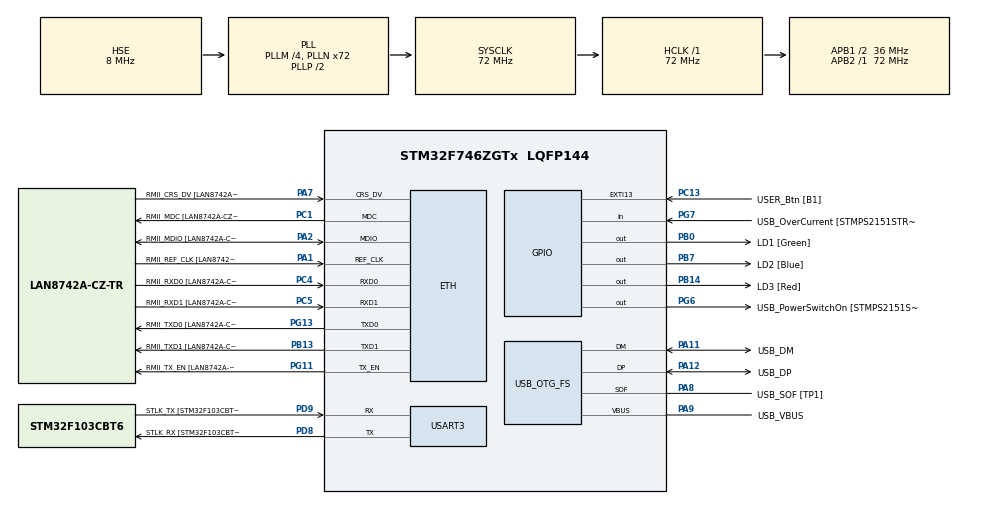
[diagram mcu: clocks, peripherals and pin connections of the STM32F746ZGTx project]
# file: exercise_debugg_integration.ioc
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ETH.MediaInterface=HAL_ETH_RMII_MODE
ETH.PHY_Name=LAN8742A_PHY_ADDRESS
ETH.PHY_Value=0
ETH.PhyAddress=0
FREERTOS.Tasks01=defaultTask,24,128,StartDefaultTask,Default,NULL,Dynamic,NULL,NULL
FREERTOS.configUSE_NEWLIB_REENTRANT=1
Mcu.Family=STM32F7
Mcu.Name=STM32F746ZGTx
Mcu.Package=LQFP144
NVIC.PriorityGroup=NVIC_PRIORITYGROUP_4
NVIC.TIM1_UP_TIM10_IRQn=true\:15\:0\:false\:false\:true\:false\:false\:true\:true
NVIC.TimeBase=TIM1_UP_TIM10_IRQn
NVIC.TimeBaseIP=TIM1
PA1.GPIO_Label=RMII_REF_CLK [LAN8742A-CZ-TR_REFCLK0]
PA1.Mode=RMII
PA1.Signal=ETH_REF_CLK
PA10.GPIO_Label=USB_ID
PA10.Signal=USB_OTG_FS_ID
PA11.GPIO_Label=USB_DM
PA11.Mode=Device_Only
PA11.Signal=USB_OTG_FS_DM
PA12.GPIO_Label=USB_DP
PA12.Mode=Device_Only
PA12.Signal=USB_OTG_FS_DP
PA13.GPIO_Label=TMS
PA13.Mode=Serial_Wire
PA13.Signal=SYS_JTMS-SWDIO
PA14.GPIO_Label=TCK
PA14.Mode=Serial_Wire
PA14.Signal=SYS_JTCK-SWCLK
PA2.GPIO_Label=RMII_MDIO [LAN8742A-CZ-TR_MDIO]
PA2.Mode=RMII
PA2.Signal=ETH_MDIO
PA7.GPIO_Label=RMII_CRS_DV [LAN8742A-CZ-TR_CRS_DV]
PA7.Mode=RMII
PA7.Signal=ETH_CRS_DV
PA8.GPIO_Label=USB_SOF [TP1]
PA8.Mode=Activate_SOF_FS
PA8.Signal=USB_OTG_FS_SOF
PA9.GPIO_Label=USB_VBUS
PA9.Mode=Activate_VBUS
PA9.Signal=USB_OTG_FS_VBUS
PB0.GPIO_Label=LD1 [Green]
PB0.Signal=GPIO_Output
PB13.GPIO_Label=RMII_TXD1 [LAN8742A-CZ-TR_TXD1]
PB13.Mode=RMII
PB13.Signal=ETH_TXD1
PB14.GPIO_Label=LD3 [Red]
PB14.Signal=GPIO_Output
PB3.GPIO_Label=SW0
PB3.Signal=SYS_JTDO-SWO
PB7.GPIO_Label=LD2 [Blue]
PB7.Signal=GPIO_Output
PC1.GPIO_Label=RMII_MDC [LAN8742A-CZ-TR_MDC]
PC1.Mode=RMII
PC1.Signal=ETH_MDC
PC13.GPIO_Label=USER_Btn [B1]
PC13.Signal=GPXTI13
PC14/OSC32_IN.Mode=LSE-External-Oscillator
PC14/OSC32_IN.Signal=RCC_OSC32_IN
PC15/OSC32_OUT.Mode=LSE-External-Oscillator
PC15/OSC32_OUT.Signal=RCC_OSC32_OUT
PC4.GPIO_Label=RMII_RXD0 [LAN8742A-CZ-TR_RXD0]
PC4.Mode=RMII
PC4.Signal=ETH_RXD0
PC5.GPIO_Label=RMII_RXD1 [LAN8742A-CZ-TR_RXD1]
PC5.Mode=RMII
PC5.Signal=ETH_RXD1
PD8.GPIO_Label=STLK_RX [STM32F103CBT6_PA3]
PD8.GPIO_PuPd=GPIO_PULLUP
PD8.Mode=Asynchronous
PD8.Signal=USART3_TX
PD9.GPIO_Label=STLK_TX [STM32F103CBT6_PA2]
PD9.GPIO_PuPd=GPIO_PULLUP
PD9.Mode=Asynchronous
PD9.Signal=USART3_RX
PG11.GPIO_Label=RMII_TX_EN [LAN8742A-CZ-TR_TXEN]
PG11.Mode=RMII
PG11.Signal=ETH_TX_EN
PG13.GPIO_Label=RMII_TXD0 [LAN8742A-CZ-TR_TXD0]
PG13.Mode=RMII
PG13.Signal=ETH_TXD0
PG6.GPIO_Label=USB_PowerSwitchOn [STMPS2151STR_EN]
PG6.Signal=GPIO_Output
PG7.GPIO_Label=USB_OverCurrent [STMPS2151STR_FAULT]
PG7.Signal=GPIO_Input
PH0/OSC_IN.GPIO_Label=MCO [STM32F103CBT6_PA8]
PH0/OSC_IN.Mode=HSE-External-Clock-Source
PH0/OSC_IN.Signal=RCC_OSC_IN
PH1/OSC_OUT.Mode=HSE-External-Clock-Source
PH1/OSC_OUT.Signal=RCC_OSC_OUT
ProjectManager.HeapSize=0x200
ProjectManager.StackSize=0x400
ProjectManager.TargetToolchain=STM32CubeIDE
RCC.48MHZClocksFreq_Value=24000000
RCC.AHBFreq_Value=72000000
RCC.APB1CLKDivider=RCC_HCLK_DIV2
RCC.APB1Freq_Value=36000000
RCC.APB1TimFreq_Value=72000000
RCC.APB2Freq_Value=72000000
RCC.APB2TimFreq_Value=72000000
RCC.CortexFreq_Value=72000000
RCC.HCLKFreq_Value=72000000
RCC.HSE_VALUE=8000000
RCC.HSI_VALUE=16000000
RCC.PLLM=4
RCC.PLLMUL=RCC_PLL_MUL9
RCC.PLLN=72
RCC.PLLQ=3
RCC.PRESCALERUSB=RCC_USBCLKSOURCE_PLL_DIV1_5
RCC.SYSCLKFreq_VALUE=72000000
RCC.SYSCLKSource=RCC_SYSCLKSOURCE_PLLCLK
RCC.SYSCLKSourceVirtual=RCC_SYSCLKSOURCE_PLLCLK
RCC.USBFreq_Value=48000000
RCC.VCOOutputFreq_Value=144000000
USART3.VirtualMode-Asynchronous=VM_ASYNC
USB_OTG_FS.VirtualMode=Device_Only
VP_FREERTOS_VS_CMSIS_V2.Mode=CMSIS_V2
VP_SYS_VS_tim1.Mode=TIM1
board=NUCLEO-F746ZG

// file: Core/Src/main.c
/* USER CODE BEGIN Header */
/**
  ******************************************************************************
  * @file           : main.c
  * @brief          : Main program body
  ******************************************************************************
  * @attention
  *
  * Copyright (c) 2024 STMicroelectronics.
  * All rights reserved.
  *
  * This software is licensed under terms that can be found in the LICENSE file
  * in the root directory of this software component.
  * If no LICENSE file comes with this software, it is provided AS-IS.
  *
  ******************************************************************************
  */
/* USER CODE END Header */
#include "main.h"
#include "string.h"
#include "freeRTOS.h"
#include "task.h"
#include <semphr.h>
#include <SEGGER_SYSVIEW.h>
#include <stm32f7xx_hal.h>
#include <lookBusy.h>

/* USER CODE BEGIN PTD */
#define STACK_SIZE 128

static void blinkTwice( LED* led );

void TaskA( void * argument);
void TaskB( void* argumet );
void TaskC( void* argumet );
/* USER CODE END PTD */

/* USER CODE BEGIN PD */

// Create storage for a pointer to a semaphore

SemaphoreHandle_t mutexPtr = NULL;

/* USER CODE END PD */

// Define the stack and the the task control block (TCB) for RedTask to use

#if defined ( __ICCARM__ ) /*!< IAR Compiler */
#pragma location=0x2004c000
ETH_DMADescTypeDef  DMARxDscrTab[ETH_RX_DESC_CNT]; /* Ethernet Rx DMA Descriptors */
#pragma location=0x2004c0a0
ETH_DMADescTypeDef  DMATxDscrTab[ETH_TX_DESC_CNT]; /* Ethernet Tx DMA Descriptors */

#elif defined ( __CC_ARM )  /* MDK ARM Compiler */

__attribute__((at(0x2004c000))) ETH_DMADescTypeDef  DMARxDscrTab[ETH_RX_DESC_CNT]; /* Ethernet Rx DMA Descriptors */
__attribute__((at(0x2004c0a0))) ETH_DMADescTypeDef  DMATxDscrTab[ETH_TX_DESC_CNT]; /* Ethernet Tx DMA Descriptors */

#elif defined ( __GNUC__ ) /* GNU Compiler */

ETH_DMADescTypeDef DMARxDscrTab[ETH_RX_DESC_CNT] __attribute__((section(".RxDecripSection"))); /* Ethernet Rx DMA Descriptors */
ETH_DMADescTypeDef DMATxDscrTab[ETH_TX_DESC_CNT] __attribute__((section(".TxDecripSection")));   /* Ethernet Tx DMA Descriptors */
#endif

ETH_TxPacketConfig TxConfig;

ETH_HandleTypeDef heth;

UART_HandleTypeDef huart3;

PCD_HandleTypeDef hpcd_USB_OTG_FS;

/* Definitions for defaultTask */

void SystemClock_Config(void);
static void MX_GPIO_Init(void);
static void MX_ETH_Init(void);
static void MX_USART3_UART_Init(void);
static void MX_USB_OTG_FS_PCD_Init(void);
void StartDefaultTask(void *argument);

uint32_t iterationsPerMilliSecond;

int main(void)
{

	BaseType_t status;
	  HAL_Init();
	  SystemClock_Config();
	  MX_GPIO_Init();
	  MX_ETH_Init();
	  MX_USART3_UART_Init();
	  MX_USB_OTG_FS_PCD_Init();

		SEGGER_SYSVIEW_Conf();
		HAL_NVIC_SetPriorityGrouping(NVIC_PRIORITYGROUP_4);	//ensure proper priority grouping for freeRTOS

		// Get the iteration-rate for lookBusy()
		    iterationsPerMilliSecond = lookBusyIterationRate();

		    // Create a mutex .
		    // Note this is just a special case of a binary semaphore.
		    mutexPtr = xSemaphoreCreateMutex();
		    assert_param(mutexPtr != NULL);

		    assert_param(xTaskCreate(TaskA, "TaskA", STACK_SIZE, NULL, tskIDLE_PRIORITY + 3, NULL) == pdPASS);
		    assert_param(xTaskCreate(TaskB, "TaskB", STACK_SIZE, NULL, tskIDLE_PRIORITY + 2, NULL) == pdPASS);
		    assert_param(xTaskCreate(TaskC, "TaskC", STACK_SIZE, NULL, tskIDLE_PRIORITY + 1, NULL) == pdPASS);

		    // Start the scheduler - shouldn't return unless there's a problem
		    vTaskStartScheduler();

		    // If you've wound up here, there is likely an issue with over-running the freeRTOS heap
		    while(1)
		    {
		    }

}

/**
 * GreenTaskA periodically 'gives' semaphorePtr
 * NOTES:
 * - This semaphore isn't "given" to any task specifically
 * - Giving the semaphore doesn't prevent GreenTaskA from continuing to run.
 * - Note the green LED continues to blink at all times
 */
/**
 * Task A is the highest priority task in the system.
 * It periodically takes the mutex with a 200ms timeout.
 * If the mutex is taken within 200 ms, the red LED is turned off,
   and blinkTwice() is called to blink the green LED.
 * If the mutex is not taken within 200ms, the red LED is turned on
   (after TaskA has been given context)
 * At the end of each while-loop iteration, vTaskDelay is called.
 */
void TaskA( void* argument )
{
    uint32_t receivedCounter = 0;
    uint32_t timedoutCounter = 0;
    while(1)
    {
        // 'take' the mutex with a 200mS timeout
        SEGGER_SYSVIEW_PrintfHost("attempt to take mutex");
        if(xSemaphoreTake(mutexPtr, 200/portTICK_PERIOD_MS) == pdPASS)
        {
        	HAL_GPIO_WritePin(GPIOB, GPIO_PIN_14, GPIO_PIN_RESET);
            receivedCounter++;
            // In calling SEGGER_SYSVIEW_PrintfHost, the space between the %u and the closing
            // quote appears to be a necessary work-around for a bug in the API.
            SEGGER_SYSVIEW_PrintfHost("received mutexPtr: %u ", receivedCounter);
            blinkTwice(&GreenLed);
            xSemaphoreGive(mutexPtr);
        }
        else
        {
            // This code is called when the mutex wasn't taken in time
            timedoutCounter++;
            SEGGER_SYSVIEW_PrintfHost("FAILED to take mutex in time: %u ", timedoutCounter);
            HAL_GPIO_WritePin(GPIOB, GPIO_PIN_14, GPIO_PIN_SET);
        }
        // Sleep for a bit to let other tasks run
        // StmRand will return a random number between 5 and 30 (inclusive).
        vTaskDelay(StmRand(5,30));
    }
}

/**
 * This medium priority task just wakes up periodically and wastes time.
 */
void TaskB( void* argument )
{
    uint32_t counter = 0;
    uint32_t spinTime;
    uint32_t i;

    while(1)
    {
        counter++;
        SEGGER_SYSVIEW_PrintfHost("starting iteration %u ", counter);
        vTaskDelay(StmRand(10,25));

        // Each for-loop iteration takes 1 ms of processing time.
        // The for-loop, as a whole, will use 30-75 ms of processing time.
        spinTime = StmRand(30,75);
        for (i=0; i<spinTime; i++){
            lookBusy(iterationsPerMilliSecond);
        }
    }
}

/**
 * The lowest priority task in the system.
 * It is the same as TaskA, except:
   * It calls blinkTwice() to blink the blue LED.
   * It does not call vTaskDelay().
 */
void TaskC( void* argument )
{
    uint32_t receivedCounter = 0;
    uint32_t timedoutCounter = 0;

    while(1)
    {
        // 'take' the mutex with a 200mS timeout
        SEGGER_SYSVIEW_PrintfHost("attempt to take mutex");
        if(xSemaphoreTake(mutexPtr, 200/portTICK_PERIOD_MS) == pdPASS)
        {
        	HAL_GPIO_WritePin(GPIOB, GPIO_PIN_14, GPIO_PIN_RESET);
            receivedCounter++;
            SEGGER_SYSVIEW_PrintfHost("mutex taken: %u ", receivedCounter);
            blinkTwice(&BlueLed);
            xSemaphoreGive(mutexPtr);
        }
        else
        {
            // This code is called when the mutex wasn't taken in time
            timedoutCounter++;
            SEGGER_SYSVIEW_PrintfHost("FAILED to take mutex in time: %u ", timedoutCounter);
            HAL_GPIO_WritePin(GPIOB, GPIO_PIN_14, GPIO_PIN_SET);
        }
    }
}

/**
 * Blink the desired LED twice
 */
static void blinkTwice( LED* led )
{
    for(uint32_t i = 0; i < 2; i++)
    {
        led->On();
        vTaskDelay(25/portTICK_PERIOD_MS);
        led->Off();
        vTaskDelay(25/portTICK_PERIOD_MS);
    }
}

void SystemClock_Config(void)
{
  RCC_OscInitTypeDef RCC_OscInitStruct = {0};
  RCC_ClkInitTypeDef RCC_ClkInitStruct = {0};

  /** Configure LSE Drive Capability
  */
  HAL_PWR_EnableBkUpAccess();

  /** Configure the main internal regulator output voltage
  */
  __HAL_RCC_PWR_CLK_ENABLE();
  __HAL_PWR_VOLTAGESCALING_CONFIG(PWR_REGULATOR_VOLTAGE_SCALE3);

  /** Initializes the RCC Oscillators according to the specified parameters
  * in the RCC_OscInitTypeDef structure.
  */
  RCC_OscInitStruct.OscillatorType = RCC_OSCILLATORTYPE_HSE;
  RCC_OscInitStruct.HSEState = RCC_HSE_BYPASS;
  RCC_OscInitStruct.PLL.PLLState = RCC_PLL_ON;
  RCC_OscInitStruct.PLL.PLLSource = RCC_PLLSOURCE_HSE;
  RCC_OscInitStruct.PLL.PLLM = 4;
  RCC_OscInitStruct.PLL.PLLN = 72;
  RCC_OscInitStruct.PLL.PLLP = RCC_PLLP_DIV2;
  RCC_OscInitStruct.PLL.PLLQ = 3;
  if (HAL_RCC_OscConfig(&RCC_OscInitStruct) != HAL_OK)
  {
    Error_Handler();
  }

  /** Initializes the CPU, AHB and APB buses clocks
  */
  RCC_ClkInitStruct.ClockType = RCC_CLOCKTYPE_HCLK|RCC_CLOCKTYPE_SYSCLK
                              |RCC_CLOCKTYPE_PCLK1|RCC_CLOCKTYPE_PCLK2;
  RCC_ClkInitStruct.SYSCLKSource = RCC_SYSCLKSOURCE_PLLCLK;
  RCC_ClkInitStruct.AHBCLKDivider = RCC_SYSCLK_DIV1;
  RCC_ClkInitStruct.APB1CLKDivider = RCC_HCLK_DIV2;
  RCC_ClkInitStruct.APB2CLKDivider = RCC_HCLK_DIV1;

  if (HAL_RCC_ClockConfig(&RCC_ClkInitStruct, FLASH_LATENCY_2) != HAL_OK)
  {
    Error_Handler();
  }
}

static void MX_ETH_Init(void)
{

   static uint8_t MACAddr[6];

  heth.Instance = ETH;
  MACAddr[0] = 0x00;
  MACAddr[1] = 0x80;
  MACAddr[2] = 0xE1;
  MACAddr[3] = 0x00;
  MACAddr[4] = 0x00;
  MACAddr[5] = 0x00;
  heth.Init.MACAddr = &MACAddr[0];
  heth.Init.MediaInterface = HAL_ETH_RMII_MODE;
  heth.Init.TxDesc = DMATxDscrTab;
  heth.Init.RxDesc = DMARxDscrTab;
  heth.Init.RxBuffLen = 1524;

  if (HAL_ETH_Init(&heth) != HAL_OK)
  {
    Error_Handler();
  }

  memset(&TxConfig, 0 , sizeof(ETH_TxPacketConfig));
  TxConfig.Attributes = ETH_TX_PACKETS_FEATURES_CSUM | ETH_TX_PACKETS_FEATURES_CRCPAD;
  TxConfig.ChecksumCtrl = ETH_CHECKSUM_IPHDR_PAYLOAD_INSERT_PHDR_CALC;
  TxConfig.CRCPadCtrl = ETH_CRC_PAD_INSERT;

}

static void MX_USART3_UART_Init(void)
{

  huart3.Instance = USART3;
  huart3.Init.BaudRate = 115200;
  huart3.Init.WordLength = UART_WORDLENGTH_8B;
  huart3.Init.StopBits = UART_STOPBITS_1;
  huart3.Init.Parity = UART_PARITY_NONE;
  huart3.Init.Mode = UART_MODE_TX_RX;
  huart3.Init.HwFlowCtl = UART_HWCONTROL_NONE;
  huart3.Init.OverSampling = UART_OVERSAMPLING_16;
  huart3.Init.OneBitSampling = UART_ONE_BIT_SAMPLE_DISABLE;
  huart3.AdvancedInit.AdvFeatureInit = UART_ADVFEATURE_NO_INIT;
  if (HAL_UART_Init(&huart3) != HAL_OK)
  {
    Error_Handler();
  }

}

static void MX_USB_OTG_FS_PCD_Init(void)
{

  hpcd_USB_OTG_FS.Instance = USB_OTG_FS;
  hpcd_USB_OTG_FS.Init.dev_endpoints = 6;
  hpcd_USB_OTG_FS.Init.speed = PCD_SPEED_FULL;
  hpcd_USB_OTG_FS.Init.dma_enable = DISABLE;
  hpcd_USB_OTG_FS.Init.phy_itface = PCD_PHY_EMBEDDED;
  hpcd_USB_OTG_FS.Init.Sof_enable = ENABLE;
  hpcd_USB_OTG_FS.Init.low_power_enable = DISABLE;
  hpcd_USB_OTG_FS.Init.lpm_enable = DISABLE;
  hpcd_USB_OTG_FS.Init.vbus_sensing_enable = ENABLE;
  hpcd_USB_OTG_FS.Init.use_dedicated_ep1 = DISABLE;
  if (HAL_PCD_Init(&hpcd_USB_OTG_FS) != HAL_OK)
  {
    Error_Handler();
  }

}

static void MX_GPIO_Init(void)
{
  GPIO_InitTypeDef GPIO_InitStruct = {0};

  /* GPIO Ports Clock Enable */
  __HAL_RCC_GPIOC_CLK_ENABLE();
  __HAL_RCC_GPIOH_CLK_ENABLE();
  __HAL_RCC_GPIOA_CLK_ENABLE();
  __HAL_RCC_GPIOB_CLK_ENABLE();
  __HAL_RCC_GPIOD_CLK_ENABLE();
  __HAL_RCC_GPIOG_CLK_ENABLE();

  /*Configure GPIO pin Output Level */
  HAL_GPIO_WritePin(GPIOB, LD1_Pin|LD3_Pin|LD2_Pin, GPIO_PIN_RESET);

  /*Configure GPIO pin Output Level */
  HAL_GPIO_WritePin(USB_PowerSwitchOn_GPIO_Port, USB_PowerSwitchOn_Pin, GPIO_PIN_RESET);

  /*Configure GPIO pin : USER_Btn_Pin */
  GPIO_InitStruct.Pin = USER_Btn_Pin;
  GPIO_InitStruct.Mode = GPIO_MODE_IT_RISING;
  GPIO_InitStruct.Pull = GPIO_NOPULL;
  HAL_GPIO_Init(USER_Btn_GPIO_Port, &GPIO_InitStruct);

  /*Configure GPIO pins : LD1_Pin LD3_Pin LD2_Pin */
  GPIO_InitStruct.Pin = LD1_Pin|LD3_Pin|LD2_Pin;
  GPIO_InitStruct.Mode = GPIO_MODE_OUTPUT_PP;
  GPIO_InitStruct.Pull = GPIO_NOPULL;
  GPIO_InitStruct.Speed = GPIO_SPEED_FREQ_LOW;
  HAL_GPIO_Init(GPIOB, &GPIO_InitStruct);

  /*Configure GPIO pin : USB_PowerSwitchOn_Pin */
  GPIO_InitStruct.Pin = USB_PowerSwitchOn_Pin;
  GPIO_InitStruct.Mode = GPIO_MODE_OUTPUT_PP;
  GPIO_InitStruct.Pull = GPIO_NOPULL;
  GPIO_InitStruct.Speed = GPIO_SPEED_FREQ_LOW;
  HAL_GPIO_Init(USB_PowerSwitchOn_GPIO_Port, &GPIO_InitStruct);

  /*Configure GPIO pin : USB_OverCurrent_Pin */
  GPIO_InitStruct.Pin = USB_OverCurrent_Pin;
  GPIO_InitStruct.Mode = GPIO_MODE_INPUT;
  GPIO_InitStruct.Pull = GPIO_NOPULL;
  HAL_GPIO_Init(USB_OverCurrent_GPIO_Port, &GPIO_InitStruct);

}

void StartDefaultTask(void *argument)
{
  for(;;)
  {
    osDelay(1);
  }
}

void HAL_TIM_PeriodElapsedCallback(TIM_HandleTypeDef *htim)
{
  if (htim->Instance == TIM1) {
    HAL_IncTick();
  }
}

void Error_Handler(void)
{
  __disable_irq();
  while (1)
  {
  }
}
